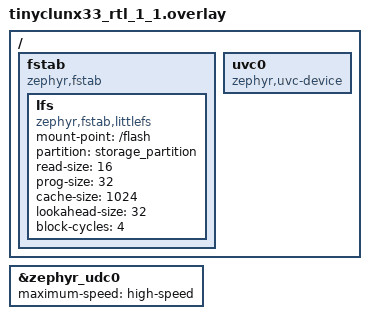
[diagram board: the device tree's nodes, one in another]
/*
 * Copyright (c) 2025 MASSDRIVER EI (massdriver.space)
 *
 * SPDX-License-Identifier: Apache-2.0
 */

/ {
	fstab {
		compatible = "zephyr,fstab";
		lfs: lfs {
			compatible = "zephyr,fstab,littlefs";
			mount-point = "/flash";
			partition = <&storage_partition>;
			read-size=<16>;
			prog-size=<32>;
			cache-size=<1024>;
			lookahead-size=<32>;
			block-cycles=<4>;
		};
	};

	uvc0: uvc0 {
		compatible = "zephyr,uvc-device";
	};
};

&zephyr_udc0 {
	maximum-speed = "high-speed";
	status = "okay";
};
